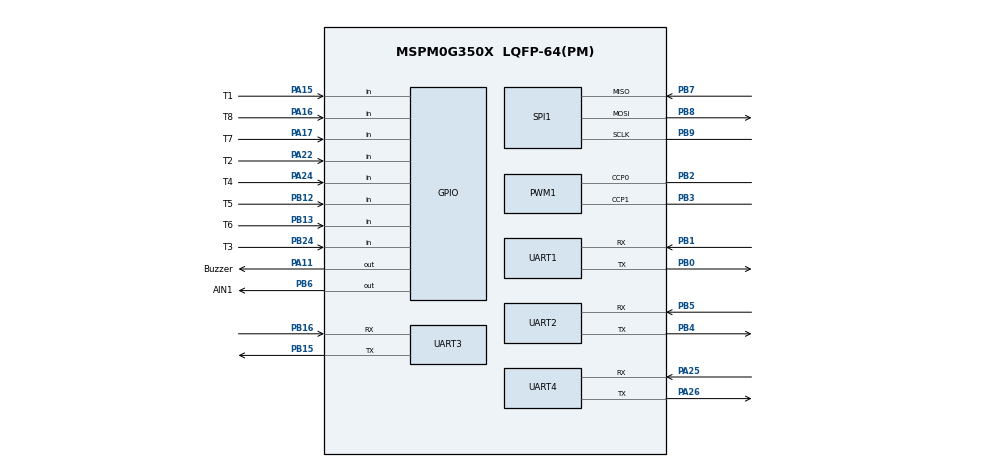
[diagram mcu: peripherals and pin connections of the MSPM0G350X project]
/**
 * @cliArgs --device "MSPM0G350X" --part "Default" --package "LQFP-64(PM)" --product "mspm0_sdk@2.10.00.04"
 * @versions {"tool":"1.26.2+4477"}
 */

/**
 * Import the modules used in this configuration.
 */
const GPIO   = scripting.addModule("/ti/driverlib/GPIO", {}, false);
const GPIO1  = GPIO.addInstance();
const GPIO2  = GPIO.addInstance();
const GPIO3  = GPIO.addInstance();
const GPIO4  = GPIO.addInstance();
const GPIO5  = GPIO.addInstance();
const GPIO6  = GPIO.addInstance();
const GPIO7  = GPIO.addInstance();
const PWM    = scripting.addModule("/ti/driverlib/PWM", {}, false);
const PWM1   = PWM.addInstance();
const SPI    = scripting.addModule("/ti/driverlib/SPI", {}, false);
const SPI1   = SPI.addInstance();
const SYSCTL = scripting.addModule("/ti/driverlib/SYSCTL");
const TIMER  = scripting.addModule("/ti/driverlib/TIMER", {}, false);
const TIMER1 = TIMER.addInstance();
const TIMER2 = TIMER.addInstance();
const TIMER3 = TIMER.addInstance();
const UART   = scripting.addModule("/ti/driverlib/UART", {}, false);
const UART1  = UART.addInstance();
const UART2  = UART.addInstance();
const UART3  = UART.addInstance();
const UART4  = UART.addInstance();

/**
 * Write custom configuration values to the imported modules.
 */
const divider9       = system.clockTree["UDIV"];
divider9.divideValue = 2;

const mux4       = system.clockTree["EXHFMUX"];
mux4.inputSelect = "EXHFMUX_XTAL";

const mux8       = system.clockTree["HSCLKMUX"];
mux8.inputSelect = "HSCLKMUX_SYSPLL2X";

const mux12       = system.clockTree["SYSPLLMUX"];
mux12.inputSelect = "zSYSPLLMUX_HFCLK";

const pinFunction4        = system.clockTree["HFXT"];
pinFunction4.enable       = true;
pinFunction4.inputFreq    = 40;
pinFunction4.HFXTStartup  = 20;
pinFunction4.HFCLKMonitor = true;

GPIO1.$name                              = "KEY";
GPIO1.associatedPins.create(4);
GPIO1.associatedPins[0].assignedPort     = "PORTB";
GPIO1.associatedPins[0].internalResistor = "PULL_UP";
GPIO1.associatedPins[0].direction        = "INPUT";
GPIO1.associatedPins[0].assignedPin      = "19";
GPIO1.associatedPins[0].$name            = "KEY_RIGHT";
GPIO1.associatedPins[1].direction        = "INPUT";
GPIO1.associatedPins[1].internalResistor = "PULL_UP";
GPIO1.associatedPins[1].assignedPort     = "PORTB";
GPIO1.associatedPins[1].assignedPin      = "17";
GPIO1.associatedPins[1].$name            = "KEY_MID";
GPIO1.associatedPins[2].$name            = "KEY_UP";
GPIO1.associatedPins[2].direction        = "INPUT";
GPIO1.associatedPins[2].assignedPort     = "PORTB";
GPIO1.associatedPins[2].assignedPin      = "20";
GPIO1.associatedPins[2].internalResistor = "PULL_UP";
GPIO1.associatedPins[3].direction        = "INPUT";
GPIO1.associatedPins[3].$name            = "KEY_LEFT";
GPIO1.associatedPins[3].assignedPort     = "PORTA";
GPIO1.associatedPins[3].assignedPin      = "14";
GPIO1.associatedPins[3].internalResistor = "PULL_UP";

const Board = scripting.addModule("/ti/driverlib/Board", {}, false);

GPIO2.$name                          = "DEBUG_LED";
GPIO2.associatedPins[0].assignedPort = "PORTB";
GPIO2.associatedPins[0].assignedPin  = "22";
GPIO2.associatedPins[0].$name        = "PIN_22";

GPIO3.$name                              = "Buzzer_Light";
GPIO3.associatedPins[0].$name            = "Buzzer";
GPIO3.associatedPins[0].internalResistor = "PULL_UP";
GPIO3.associatedPins[0].assignedPin      = "11";
GPIO3.associatedPins[0].assignedPort     = "PORTA";
GPIO3.associatedPins[0].pin.$assign      = "PA11";

GPIO4.$name                          = "TB6612";
GPIO4.associatedPins.create(4);
GPIO4.associatedPins[0].$name        = "AIN1";
GPIO4.associatedPins[0].initialValue = "SET";
GPIO4.associatedPins[0].assignedPort = "PORTB";
GPIO4.associatedPins[0].assignedPin  = "6";
GPIO4.associatedPins[0].pin.$assign  = "PB6";
GPIO4.associatedPins[1].$name        = "AIN2";
GPIO4.associatedPins[1].initialValue = "SET";
GPIO4.associatedPins[1].assignedPort = "PORTA";
GPIO4.associatedPins[1].assignedPin  = "12";
GPIO4.associatedPins[2].$name        = "BIN1";
GPIO4.associatedPins[2].assignedPort = "PORTB";
GPIO4.associatedPins[2].assignedPin  = "23";
GPIO4.associatedPins[2].initialValue = "SET";
GPIO4.associatedPins[3].$name        = "BIN2";
GPIO4.associatedPins[3].initialValue = "SET";
GPIO4.associatedPins[3].assignedPort = "PORTB";
GPIO4.associatedPins[3].assignedPin  = "27";

GPIO5.$name                               = "ENCODER";
GPIO5.associatedPins.create(4);
GPIO5.associatedPins[0].$name             = "E1A";
GPIO5.associatedPins[0].direction         = "INPUT";
GPIO5.associatedPins[0].assignedPort      = "PORTA";
GPIO5.associatedPins[0].assignedPin       = "1";
GPIO5.associatedPins[0].interruptEn       = true;
GPIO5.associatedPins[0].interruptPriority = "0";
GPIO5.associatedPins[0].polarity          = "RISE";
GPIO5.associatedPins[1].$name             = "E1B";
GPIO5.associatedPins[1].direction         = "INPUT";
GPIO5.associatedPins[1].assignedPort      = "PORTA";
GPIO5.associatedPins[1].assignedPin       = "00";
GPIO5.associatedPins[1].interruptEn       = true;
GPIO5.associatedPins[1].interruptPriority = "0";
GPIO5.associatedPins[1].polarity          = "RISE";
GPIO5.associatedPins[2].$name             = "E2A";
GPIO5.associatedPins[2].assignedPort      = "PORTA";
GPIO5.associatedPins[2].assignedPin       = "8";
GPIO5.associatedPins[2].direction         = "INPUT";
GPIO5.associatedPins[2].interruptEn       = true;
GPIO5.associatedPins[2].interruptPriority = "0";
GPIO5.associatedPins[2].polarity          = "RISE";
GPIO5.associatedPins[3].$name             = "E2B";
GPIO5.associatedPins[3].direction         = "INPUT";
GPIO5.associatedPins[3].assignedPort      = "PORTA";
GPIO5.associatedPins[3].assignedPin       = "9";
GPIO5.associatedPins[3].interruptEn       = true;
GPIO5.associatedPins[3].interruptPriority = "0";
GPIO5.associatedPins[3].polarity          = "RISE";

GPIO6.$name                         = "LCD";
GPIO6.port                          = "PORTB";
GPIO6.associatedPins.create(4);
GPIO6.associatedPins[0].$name       = "RES";
GPIO6.associatedPins[0].ioStructure = "SD";
GPIO6.associatedPins[0].assignedPin = "10";
GPIO6.associatedPins[1].$name       = "DC";
GPIO6.associatedPins[1].ioStructure = "SD";
GPIO6.associatedPins[1].assignedPin = "11";
GPIO6.associatedPins[2].$name       = "CS";
GPIO6.associatedPins[2].ioStructure = "SD";
GPIO6.associatedPins[2].assignedPin = "14";
GPIO6.associatedPins[3].$name       = "BLK";
GPIO6.associatedPins[3].ioStructure = "SD";
GPIO6.associatedPins[3].assignedPin = "26";

GPIO7.$name                          = "Track";
GPIO7.associatedPins.create(8);
GPIO7.associatedPins[0].$name        = "T1";
GPIO7.associatedPins[0].direction    = "INPUT";
GPIO7.associatedPins[0].assignedPort = "PORTA";
GPIO7.associatedPins[0].assignedPin  = "15";
GPIO7.associatedPins[0].pin.$assign  = "PA15";
GPIO7.associatedPins[1].$name        = "T2";
GPIO7.associatedPins[1].direction    = "INPUT";
GPIO7.associatedPins[1].assignedPort = "PORTA";
GPIO7.associatedPins[1].assignedPin  = "22";
GPIO7.associatedPins[1].pin.$assign  = "PA22";
GPIO7.associatedPins[2].$name        = "T3";
GPIO7.associatedPins[2].direction    = "INPUT";
GPIO7.associatedPins[2].assignedPort = "PORTB";
GPIO7.associatedPins[2].assignedPin  = "24";
GPIO7.associatedPins[2].pin.$assign  = "PB24";
GPIO7.associatedPins[3].$name        = "T4";
GPIO7.associatedPins[3].direction    = "INPUT";
GPIO7.associatedPins[3].assignedPort = "PORTA";
GPIO7.associatedPins[3].assignedPin  = "24";
GPIO7.associatedPins[3].pin.$assign  = "PA24";
GPIO7.associatedPins[4].$name        = "T5";
GPIO7.associatedPins[4].direction    = "INPUT";
GPIO7.associatedPins[4].assignedPort = "PORTB";
GPIO7.associatedPins[4].assignedPin  = "12";
GPIO7.associatedPins[4].pin.$assign  = "PB12";
GPIO7.associatedPins[5].$name        = "T6";
GPIO7.associatedPins[5].direction    = "INPUT";
GPIO7.associatedPins[5].assignedPort = "PORTB";
GPIO7.associatedPins[5].assignedPin  = "13";
GPIO7.associatedPins[5].pin.$assign  = "PB13";
GPIO7.associatedPins[6].$name        = "T7";
GPIO7.associatedPins[6].direction    = "INPUT";
GPIO7.associatedPins[6].assignedPort = "PORTA";
GPIO7.associatedPins[6].assignedPin  = "17";
GPIO7.associatedPins[6].pin.$assign  = "PA17";
GPIO7.associatedPins[7].$name        = "T8";
GPIO7.associatedPins[7].direction    = "INPUT";
GPIO7.associatedPins[7].assignedPin  = "16";
GPIO7.associatedPins[7].assignedPort = "PORTA";
GPIO7.associatedPins[7].pin.$assign  = "PA16";

PWM1.$name                      = "PWM_0";
PWM1.timerStartTimer            = true;
PWM1.timerCount                 = 10000;
PWM1.peripheral.$assign         = "TIMA1";
PWM1.peripheral.ccp0Pin.$assign = "PB2";
PWM1.peripheral.ccp1Pin.$assign = "PB3";
PWM1.PWM_CHANNEL_0.$name        = "ti_driverlib_pwm_PWMTimerCC0";
PWM1.PWM_CHANNEL_0.invert       = true;
PWM1.PWM_CHANNEL_1.$name        = "ti_driverlib_pwm_PWMTimerCC1";
PWM1.PWM_CHANNEL_1.invert       = true;
PWM1.ccp0PinConfig.$name        = "ti_driverlib_gpio_GPIOPinGeneric0";
PWM1.ccp1PinConfig.$name        = "ti_driverlib_gpio_GPIOPinGeneric1";

SPI1.$name                              = "SPI_LCD";
SPI1.targetBitRate                      = 1000000;
SPI1.frameFormat                        = "MOTO3";
SPI1.polarity                           = "1";
SPI1.sclkPinConfig.direction            = scripting.forceWrite("OUTPUT");
SPI1.sclkPinConfig.onlyInternalResistor = scripting.forceWrite(false);
SPI1.sclkPinConfig.passedPeripheralType = scripting.forceWrite("Digital");
SPI1.sclkPinConfig.$name                = "ti_driverlib_gpio_GPIOPinGeneric8";
SPI1.mosiPinConfig.direction            = scripting.forceWrite("OUTPUT");
SPI1.mosiPinConfig.hideOutputInversion  = scripting.forceWrite(false);
SPI1.mosiPinConfig.onlyInternalResistor = scripting.forceWrite(false);
SPI1.mosiPinConfig.passedPeripheralType = scripting.forceWrite("Digital");
SPI1.mosiPinConfig.$name                = "ti_driverlib_gpio_GPIOPinGeneric11";
SPI1.misoPinConfig.onlyInternalResistor = scripting.forceWrite(false);
SPI1.misoPinConfig.passedPeripheralType = scripting.forceWrite("Digital");
SPI1.misoPinConfig.$name                = "ti_driverlib_gpio_GPIOPinGeneric12";
SPI1.peripheral.sclkPin.$assign         = "PB9";
SPI1.peripheral.mosiPin.$assign         = "PB8";
SPI1.peripheral.misoPin.$assign         = "PB7";

SYSCTL.forceDefaultClkConfig = true;
SYSCTL.clockTreeEn           = true;
SYSCTL.validateClkStatus     = true;

TIMER1.$name              = "TIMER_0";
TIMER1.timerMode          = "PERIODIC";
TIMER1.timerStartTimer    = true;
TIMER1.interrupts         = ["ZERO"];
TIMER1.timerClkDiv        = 2;
TIMER1.timerClkPrescale   = 25;
TIMER1.interruptPriority  = "3";
TIMER1.timerPeriod        = "10ms";
TIMER1.peripheral.$assign = "TIMG0";

TIMER2.$name              = "TIMER_1";
TIMER2.timerClkDiv        = 8;
TIMER2.timerMode          = "PERIODIC";
TIMER2.timerPeriod        = "05ms";
TIMER2.timerStartTimer    = true;
TIMER2.interrupts         = ["ZERO"];
TIMER2.interruptPriority  = "2";
TIMER2.peripheral.$assign = "TIMA0";

TIMER3.$name              = "STEP_TIM";
TIMER3.timerClkDiv        = 8;
TIMER3.timerStartTimer    = true;
TIMER3.timerMode          = "PERIODIC";
TIMER3.timerPeriod        = "0.1ms";
TIMER3.peripheral.$assign = "TIMG6";

UART1.$name                    = "UART_0";
UART1.uartClkDiv               = "4";
UART1.enabledInterrupts        = ["RX"];
UART1.peripheral.$assign       = "UART0";
UART1.peripheral.rxPin.$assign = "PB1";
UART1.peripheral.txPin.$assign = "PB0";
UART1.txPinConfig.$name        = "ti_driverlib_gpio_GPIOPinGeneric2";
UART1.txPinConfig.enableConfig = true;
UART1.rxPinConfig.$name        = "ti_driverlib_gpio_GPIOPinGeneric3";
UART1.rxPinConfig.enableConfig = true;

UART2.$name                    = "UART_1";
UART2.targetBaudRate           = 115200;
UART2.enabledInterrupts        = ["RX"];
UART2.interruptPriority        = "1";
UART2.peripheral.$assign       = "UART1";
UART2.peripheral.rxPin.$assign = "PB5";
UART2.peripheral.txPin.$assign = "PB4";
UART2.txPinConfig.$name        = "ti_driverlib_gpio_GPIOPinGeneric4";
UART2.txPinConfig.enableConfig = true;
UART2.rxPinConfig.$name        = "ti_driverlib_gpio_GPIOPinGeneric5";
UART2.rxPinConfig.enableConfig = true;

UART3.$name                    = "UART_2";
UART3.targetBaudRate           = 115200;
UART3.enabledInterrupts        = ["RX"];
UART3.interruptPriority        = "1";
UART3.peripheral.$assign       = "UART2";
UART3.peripheral.rxPin.$assign = "PB16";
UART3.peripheral.txPin.$assign = "PB15";
UART3.txPinConfig.$name        = "ti_driverlib_gpio_GPIOPinGeneric6";
UART3.txPinConfig.enableConfig = true;
UART3.rxPinConfig.$name        = "ti_driverlib_gpio_GPIOPinGeneric7";
UART3.rxPinConfig.enableConfig = true;

UART4.$name                    = "UART_3";
UART4.targetBaudRate           = 115200;
UART4.enabledInterrupts        = ["RX"];
UART4.interruptPriority        = "1";
UART4.peripheral.$assign       = "UART3";
UART4.peripheral.rxPin.$assign = "PA25";
UART4.peripheral.txPin.$assign = "PA26";
UART4.txPinConfig.$name        = "ti_driverlib_gpio_GPIOPinGeneric9";
UART4.txPinConfig.enableConfig = true;
UART4.rxPinConfig.$name        = "ti_driverlib_gpio_GPIOPinGeneric10";
UART4.rxPinConfig.enableConfig = true;

const ProjectConfig              = scripting.addModule("/ti/project_config/ProjectConfig", {}, false);
ProjectConfig.migrationCondition = true;

/**
 * Pinmux solution for unlocked pins/peripherals. This ensures that minor changes to the automatic solver in a future
 * version of the tool will not impact the pinmux you originally saw.  These lines can be completely deleted in order to
 * re-solve from scratch.
 */
pinFunction4.peripheral.$suggestSolution           = "SYSCTL";
pinFunction4.peripheral.hfxInPin.$suggestSolution  = "PA5";
pinFunction4.peripheral.hfxOutPin.$suggestSolution = "PA6";
GPIO1.associatedPins[0].pin.$suggestSolution       = "PB19";
GPIO1.associatedPins[1].pin.$suggestSolution       = "PB17";
GPIO1.associatedPins[2].pin.$suggestSolution       = "PB20";
GPIO1.associatedPins[3].pin.$suggestSolution       = "PA14";
Board.peripheral.$suggestSolution                  = "DEBUGSS";
Board.peripheral.swclkPin.$suggestSolution         = "PA20";
Board.peripheral.swdioPin.$suggestSolution         = "PA19";
GPIO2.associatedPins[0].pin.$suggestSolution       = "PB22";
GPIO4.associatedPins[1].pin.$suggestSolution       = "PA12";
GPIO4.associatedPins[2].pin.$suggestSolution       = "PB23";
GPIO4.associatedPins[3].pin.$suggestSolution       = "PB27";
GPIO5.associatedPins[0].pin.$suggestSolution       = "PA1";
GPIO5.associatedPins[1].pin.$suggestSolution       = "PA0";
GPIO5.associatedPins[2].pin.$suggestSolution       = "PA8";
GPIO5.associatedPins[3].pin.$suggestSolution       = "PA9";
GPIO6.associatedPins[0].pin.$suggestSolution       = "PB10";
GPIO6.associatedPins[1].pin.$suggestSolution       = "PB11";
GPIO6.associatedPins[2].pin.$suggestSolution       = "PB14";
GPIO6.associatedPins[3].pin.$suggestSolution       = "PB26";
SPI1.peripheral.$suggestSolution                   = "SPI1";
